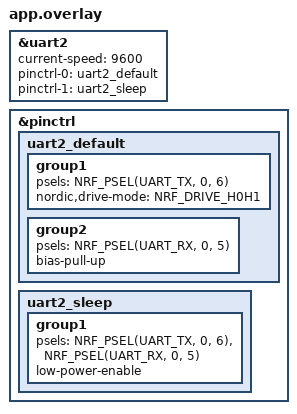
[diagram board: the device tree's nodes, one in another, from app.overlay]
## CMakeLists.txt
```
# SPDX-License-Identifier: Apache-2.0

cmake_minimum_required(VERSION 3.20.0)

include(FetchContent)

find_package(Zephyr REQUIRED HINTS $ENV{ZEPHYR_BASE})
project(fog)

FetchContent_Declare(
  fmt
  GIT_REPOSITORY https://github.com/fmtlib/fmt
  GIT_TAG        e69e5f977d458f2650bb346dadf2ad30c5320281) # 10.2.1
FetchContent_MakeAvailable(fmt)

target_include_directories(app PRIVATE src)
target_include_directories(app PRIVATE ../)
target_link_libraries(app PRIVATE fmt::fmt)

target_include_directories(app PRIVATE src)

target_sources(app PRIVATE
    src/main.cpp
    src/raft/coap/coap.cpp
    ../common/coap_utils.c
)

include(${ZEPHYR_BASE}/samples/net/common/common.cmake)

set(gen_dir ${ZEPHYR_BINARY_DIR}/include/generated/)
```

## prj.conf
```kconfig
CONFIG_NETWORKING=y
CONFIG_NET_L2_OPENTHREAD=y
CONFIG_OPENTHREAD_COAP=y
CONFIG_OPENTHREAD_SLAAC=y
CONFIG_OPENTHREAD_TIME_SYNC=y
CONFIG_OPENTHREAD_ENABLE_SERVICE=y
CONFIG_JSON_LIBRARY=y

# Logging
# CONFIG_LOG=y
# CONFIG_LOG_MAX_LEVEL=4
# CONFIG_LOG_MODE_MINIMAL=y
# CONFIG_BOOT_BANNER=y
# CONFIG_LOG_BACKEND_UART=y

CONFIG_LOG=y
CONFIG_LOG_MAX_LEVEL=4
CONFIG_LOG_MODE_MINIMAL=y
CONFIG_BOOT_BANNER=y
CONFIG_USE_SEGGER_RTT=y
CONFIG_RTT_CONSOLE=y
CONFIG_LOG_BACKEND_RTT=y
CONFIG_UART_CONSOLE=n
CONFIG_LOG_BACKEND_UART=n

# Kernel options
CONFIG_MAIN_STACK_SIZE=8192
CONFIG_SYSTEM_WORKQUEUE_STACK_SIZE=16384
CONFIG_OPENTHREAD_THREAD_STACK_SIZE=8192
CONFIG_INIT_STACKS=y

# Serial and UART
CONFIG_SERIAL=y
CONFIG_UART_INTERRUPT_DRIVEN=y

# Modem subsystem
CONFIG_MODEM_PIPE=y
CONFIG_MODEM_CHAT=y
CONFIG_MODEM_MODULES=y
CONFIG_MODEM_BACKEND_UART=y
CONFIG_MODEM_MODULES_LOG_LEVEL_DBG=y

# Add features required for FTD CLI
CONFIG_SHELL=y
CONFIG_OPENTHREAD_SHELL=y
CONFIG_OPENTHREAD_PING_SENDER=y

# Network config
CONFIG_OPENTHREAD_PANID=4660
CONFIG_OPENTHREAD_XPANID="11:11:11:11:22:22:22:22"
CONFIG_OPENTHREAD_NETWORKKEY="00:11:22:33:44:55:66:77:88:99:aa:bb:cc:dd:ee:ff"
CONFIG_OPENTHREAD_CHANNEL=15
CONFIG_OPENTHREAD_NETWORK_NAME="Fog"

# Flash and persistence
CONFIG_FLASH=y
CONFIG_FLASH_MAP=y
CONFIG_NVS=y
CONFIG_SETTINGS=y

CONFIG_CPP=y
CONFIG_STD_CPP23=y
CONFIG_GLIBCXX_LIBCPP=y

# PSA key generation
CONFIG_PSA_WANT_KEY_TYPE_ECC_KEY_PAIR_EXPORT=y     # export the public half for provisioning
CONFIG_PSA_WANT_KEY_TYPE_ECC_PUBLIC_KEY=y          # import peers' public keys for verification

# PSA crypto backend
CONFIG_PSA_WANT_ALG_ECDH=y
CONFIG_PSA_WANT_ALG_ECDSA=y
CONFIG_PSA_WANT_ALG_SHA_256=y
CONFIG_PSA_WANT_ECC_SECP_R1_256=y
CONFIG_PSA_WANT_ALG_CCM=y

CONFIG_MBEDTLS_PSA_CRYPTO_C=y
CONFIG_MBEDTLS_ENABLE_HEAP=y

CONFIG_HW_UNIQUE_KEY=y
CONFIG_HW_UNIQUE_KEY_RANDOM=y
CONFIG_HW_UNIQUE_KEY_LOAD=y
# CONFIG_NRF_SECURITY=y

CONFIG_PSA_WANT_KEY_TYPE_ECC_KEY_PAIR_IMPORT=y

CONFIG_BUILD_WITH_TFM=y

CONFIG_SECURE_BOOT=n
CONFIG_TFM_PROFILE_TYPE_MINIMAL=y

CONFIG_HWINFO=y
```

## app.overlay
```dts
&uart2 {
    status = "okay";
    current-speed = <9600>;

    pinctrl-0 = <&uart2_default>;
    pinctrl-1 = <&uart2_sleep>;
    pinctrl-names = "default", "sleep";
};

&pinctrl {
    uart2_default: uart2_default {
        group1 {
            psels = <NRF_PSEL(UART_TX, 0, 6)>;
            nordic,drive-mode = <NRF_DRIVE_H0H1>;
        };
        group2 {
            psels = <NRF_PSEL(UART_RX, 0, 5)>;
            bias-pull-up;
        };
    };

    uart2_sleep: uart2_sleep {
        group1 {
            psels = <NRF_PSEL(UART_TX, 0, 6)>,
                    <NRF_PSEL(UART_RX, 0, 5)>;
            low-power-enable;
        };
    };
};
```

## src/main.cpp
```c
#include "application.hpp"
#include "common/coap_utils.h"
#include "common/logging.hpp"
#include "psa/crypto.h"
#include <optional>

namespace {

/** @brief Flag to handle reattaching to openthread network. */
bool s_initialised = false;

std::optional<fog::Application> app;

/**
 * @brief OpenThread state change callback.
 * @param flags Flags to check on state change.
 * @param user_data unused.
 */
void on_thread_state_changed(otChangedFlags flags, void *user_data) {

  ARG_UNUSED(user_data);

  otInstance *const inst = openthread_get_default_instance();

  if ((flags & OT_CHANGED_THREAD_ROLE) != 0) {
    const otDeviceRole role = otThreadGetDeviceRole(inst);
    switch (role) {
    case OT_DEVICE_ROLE_CHILD:
    case OT_DEVICE_ROLE_ROUTER:
    case OT_DEVICE_ROLE_LEADER:
      // We have a valid role so start.
      if (!s_initialised) {
        logging::wrn("Device attached started raft.");
        app->init();
        app->start();
        s_initialised = true;
      }
      break;

    case OT_DEVICE_ROLE_DISABLED:
    case OT_DEVICE_ROLE_DETACHED:
    default:
      logging::wrn("Device detached from thread network.");
      break;
    }
  }
}

/**
 * @brief State change callback structure, used to register to callback with
 * openthread.
 */
struct openthread_state_changed_callback s_ot_state_chaged_cb = {
    .otCallback = on_thread_state_changed};

} // namespace

int main(void) {

  const auto ret = coap_init();
  if (ret != 0) {
    return ret;
  }

  psa_crypto_init();

  app.emplace();

  openthread_state_changed_callback_register(&s_ot_state_chaged_cb);
  openthread_run();
}
```

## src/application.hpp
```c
#pragma once

#include "common/alert.hpp"
#include "common/global_config.h"
#include "common/logging.hpp"
#include "common/ot_utils.hpp"
#include "common/security/trusted_device_store.hpp"
#include "common/security/trusted_devices.hpp"
#include "common/sensor_reading.hpp"
#include "egress/egress_coordinator.hpp"
#include "lorawan/service.hpp"
#include "outlier_vote/engine.hpp"
#include "outlier_vote/sensor_batch.hpp"
#include "outlier_vote/service.hpp"
#include "raft/engine.hpp"
#include "raft/raft_types.hpp"
// #include "secrets/provisioned_keys.hpp"
// Example keys
#include "provisioned_keys.example.hpp"
#include "sensor/service.hpp"
#include "utils/time_sync.h"
#include "zephyr/kernel.h"
#include <cassert>
#include <type_traits>

namespace fog {

/**
 * @brief The main application.
 */
class Application {

public:
  /**
   * @brief Initialise all sub components.
   */
  void init() {
    const auto eui = common::get_eui64_as_uint64();
    if (const auto err = m_trusted_device_store.init(eui); err != PSA_SUCCESS) {
      logging::err("Failed to initialise trust store.");
      return;
    }

    if (const auto err = m_trusted_device_store.trust_peers(TRUSTED_DEVICES);
        err != PSA_SUCCESS) {
      logging::err("Failed to initialise trust store.");
      return;
    }

    const auto pub_key = m_trusted_device_store.export_pubkey();
    if (pub_key.has_value()) {
      logging::inf(".eui={:#x}, .pub_key={::#x}", common::get_eui64_as_uint64(),
                   pub_key.value());
    }

    if (!m_lora_service.init()) {
      logging::err("Failed to initialise LoRaWAN service.");
      return;
    }

    m_sensor_service.init();
    m_raft_engine.init();
    m_alert_service.init();
  }

  /**
   * @brief Start all sub components.
   */
  void start() {
    m_vote_service.start();
    m_raft_engine.start();
  }

  /** @brief Stop the LoRaWAN thread. */
  void stop() { m_lora_service.stop(); }

  static constexpr std::uint16_t ALERT_INTERVAL_MS = common::ALERT_TIMEOUT_MS;

private:
  /**
   * @brief Called by raft when it applies.
   * @param [in] entry
   */
  void on_apply(const raft::Server<>::EntryT &entry) {

    if (entry.m_type == raft::EntryType::EGRESS_MSG) {
      egress::EgressRecord egr;
      if (entry.m_data_len == sizeof(egr)) {
        std::memcpy(&egr, &entry.m_data, sizeof(egr));
        m_egress_coordinator.on_egress_applied(egr);
      }
    } else if (entry.m_type == raft::EntryType::SENSOR_DATA) {
      // On submit check for an alert and sens immediately.
      check_alert(entry);
      // The egress coordinator will start the message to the gateway.
      m_egress_coordinator.begin_egress(entry.m_index);
    }
  }

  /**
   * @brief Check the entry for an alert and emit the alert to all peers.
   * @param [in] entry The entry
   */
  void check_alert(const raft::Server<>::EntryT &entry) {
    assert(entry.m_type == raft::EntryType::SENSOR_DATA);

    batch::SensorBatch batch;
    std::memcpy(&batch, entry.m_data.data(), sizeof(batch));

    // State hasn't changed, nothing to do.
    if (batch.m_alert_active == m_alert_active) {
      return;
    }

    m_alert_active = batch.m_alert_active;
    const auto eui = common::get_eui64_as_uint64();

    if (m_alert_active) {
      m_alert_service.send_alert(eui, {.m_alert_interval_ms = ALERT_INTERVAL_MS,
                                       .m_alert_active = true});
      m_vote_service.set_collection_window(ALERT_INTERVAL_MS);
    } else {
      m_alert_service.send_alert(
          eui, {.m_alert_interval_ms = 0, .m_alert_active = false});
      m_vote_service.set_collection_window(
          vote::OutlierVoteConfig::m_collection_window_ms);
    }

    m_vote_service.resync();
  }

  /**
   * @brief Configure the hooks for the egress coordinator.
   * @return egress::Hooks<raft::Server<>::EntryT, batch::SensorBatch>
   */
  egress::Hooks<raft::Server<>::EntryT, batch::SensorBatch>
  make_egress_hooks() {
    return {.m_is_leader = [this] { return m_raft_engine.is_leader(); },
            // Submit an egress record to raft.
            .m_submit_egress =
                [this](const egress::EgressRecord &rec) {
                  return m_raft_engine
                      .submit(raft::EntryType::EGRESS_MSG,
                              std::span(std::bit_cast<const std::byte *>(&rec),
                                        sizeof(rec)))
                      .has_value();
                },
            // Read an entry from raft
            .m_read_entry =
                [this](const std::uint64_t index) {
                  return m_raft_engine.get_entry(index);
                },
            // Submit the batch to LoRaWAN
            .m_lorawan_send =
                [this](const batch::SensorBatch &batch, std::uint64_t term,
                       std::uint64_t index, std::uint32_t seq) {
                  (void)m_lora_service.send_batch(batch, term, index, seq);
                }};
  }

  common::Eui64Arr m_eui = common::get_eui64_as_arr8();

  lora::LoraWanService m_lora_service{lora::Platform{
      .uart = DEVICE_DT_GET(DT_NODELABEL(uart2)),
      .eui = m_eui,
      .app_key = LORAWAN_APP_KEY,
      .m_on_complete = [this](std::uint32_t seq, std::uint64_t batch_index) {
        m_egress_coordinator.on_lorawan_ok(seq, batch_index);
      }}};

  /** @brief Raft configuration. */
  raft::Engine m_raft_engine{
      [this](const auto &entry) { on_apply(entry); },

      // State change.
      [this](const raft::State old_state, const raft::State new_state) {
        logging::inf("State changed from: {} to: {}", to_string(old_state),
                     to_string(new_state));

        if (new_state == raft::State::LEADER) {
#ifdef CONFIG_ENABLE_FAULT_INJECTION
          logging::inf("RAFT:BECAME_LEADER");
#endif
          m_egress_coordinator.on_became_leader();
        }
#ifdef CONFIG_ENABLE_FAULT_INJECTION
        else if (new_state == raft::State::FOLLOWER) {
          logging::inf("RAFT:BECAME_FOLLOWER");
        }
#endif
      },
      common::get_eui64_as_uint64(), m_trusted_device_store};

  /** @brief Outlier vote service. */
  vote::VoteService m_vote_service{
      // Called when a new back has been received by the outlier vote layer.
      [this](const batch::SensorBatch &batch) {
        if (const auto err = m_raft_engine.submit(
                raft::EntryType::SENSOR_DATA,
                std::span(std::bit_cast<const std::byte *>(&batch),
                          sizeof(batch)));
            !err.has_value()) {
          logging::err(
              "Submit failed: .err={}",
              static_cast<std::underlying_type_t<raft::Error>>(err.error()));
        }
      },
      // Get the current time.
      [] -> std::optional<std::uint64_t> {
        if (const auto time_us = time_sync::get_time_us()) {
          return time_us.value() / 1000;
        }
        return k_uptime_seconds() * 1000;
      }};

  /** @brief Sensor service for collecting readings */
  sensor::Service m_sensor_service{
      common::SENSOR_URI,
      [this](const common::SensorReadingWire &reading) {
        m_vote_service.accumulate(reading);
      },
      m_trusted_device_store};

  /** @brief Handling replicating egress status amongst fellow fog nodes. */
  egress::EgressCoordinator<raft::Server<>::EntryT, batch::SensorBatch>
      m_egress_coordinator{make_egress_hooks()};

  /** @brief Handle receiving alert messages.. */
  common::Alert m_alert_service{[this](const auto alert) {
    // Ignore if we sent the message.
    if (m_raft_engine.is_leader()) {
      return;
    }

    if (alert.m_alert_active) {
      // Set the alert time and resync the timeout window.
      logging::inf("Received an active alert, changing period to: {} s",
                   alert.m_alert_interval_ms);
      auto alert_ms = alert.m_alert_interval_ms;
      m_vote_service.set_collection_window(alert_ms);
      m_vote_service.resync();
    } else {
      // Reset the alert time.
      logging::inf("Alert cancelled", alert.m_alert_interval_ms);
      m_vote_service.set_collection_window(
          vote::OutlierVoteConfig::m_collection_window_ms);
      m_vote_service.resync();
    }
  }};

  /** @brief Trusted devices for signing messages. */
  common::TrustedDeviceStore m_trusted_device_store;

  /** @brief Is an alert active. */
  bool m_alert_active;
};

} // namespace fog
```

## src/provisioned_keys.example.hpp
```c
#pragma once
#include <array>
#include <cstdint>
#include <string_view>

/**
 * @brief Example keys required by application.hpp
 */

static constexpr std::uint16_t PANID = 0x00;
static constexpr std::uint8_t XPANID[] = {
    0x00, 0x00, 0x00, 0x00, 0x00, 0x00, 0x00, 0x00,
};
static constexpr std::uint8_t NETWORK_KEY[] = {
    0x00, 0x00, 0x00, 0x00, 0x00, 0x00, 0x00, 0x00,
    0x00, 0x00, 0x00, 0x00, 0x00, 0x00, 0x00, 0x00,
};

static constexpr std::string_view LORAWAN_APP_KEY =
    "00000000000000000000000000000000";

static constexpr std::array<std::uint8_t, 16> LORAWAN_APP_KEY_ARR = {
    0x00, 0x00, 0x00, 0x00, 0x00, 0x00, 0x00, 0x00,
    0x00, 0x00, 0x00, 0x00, 0x00, 0x00, 0x00, 0x00,
};
```
